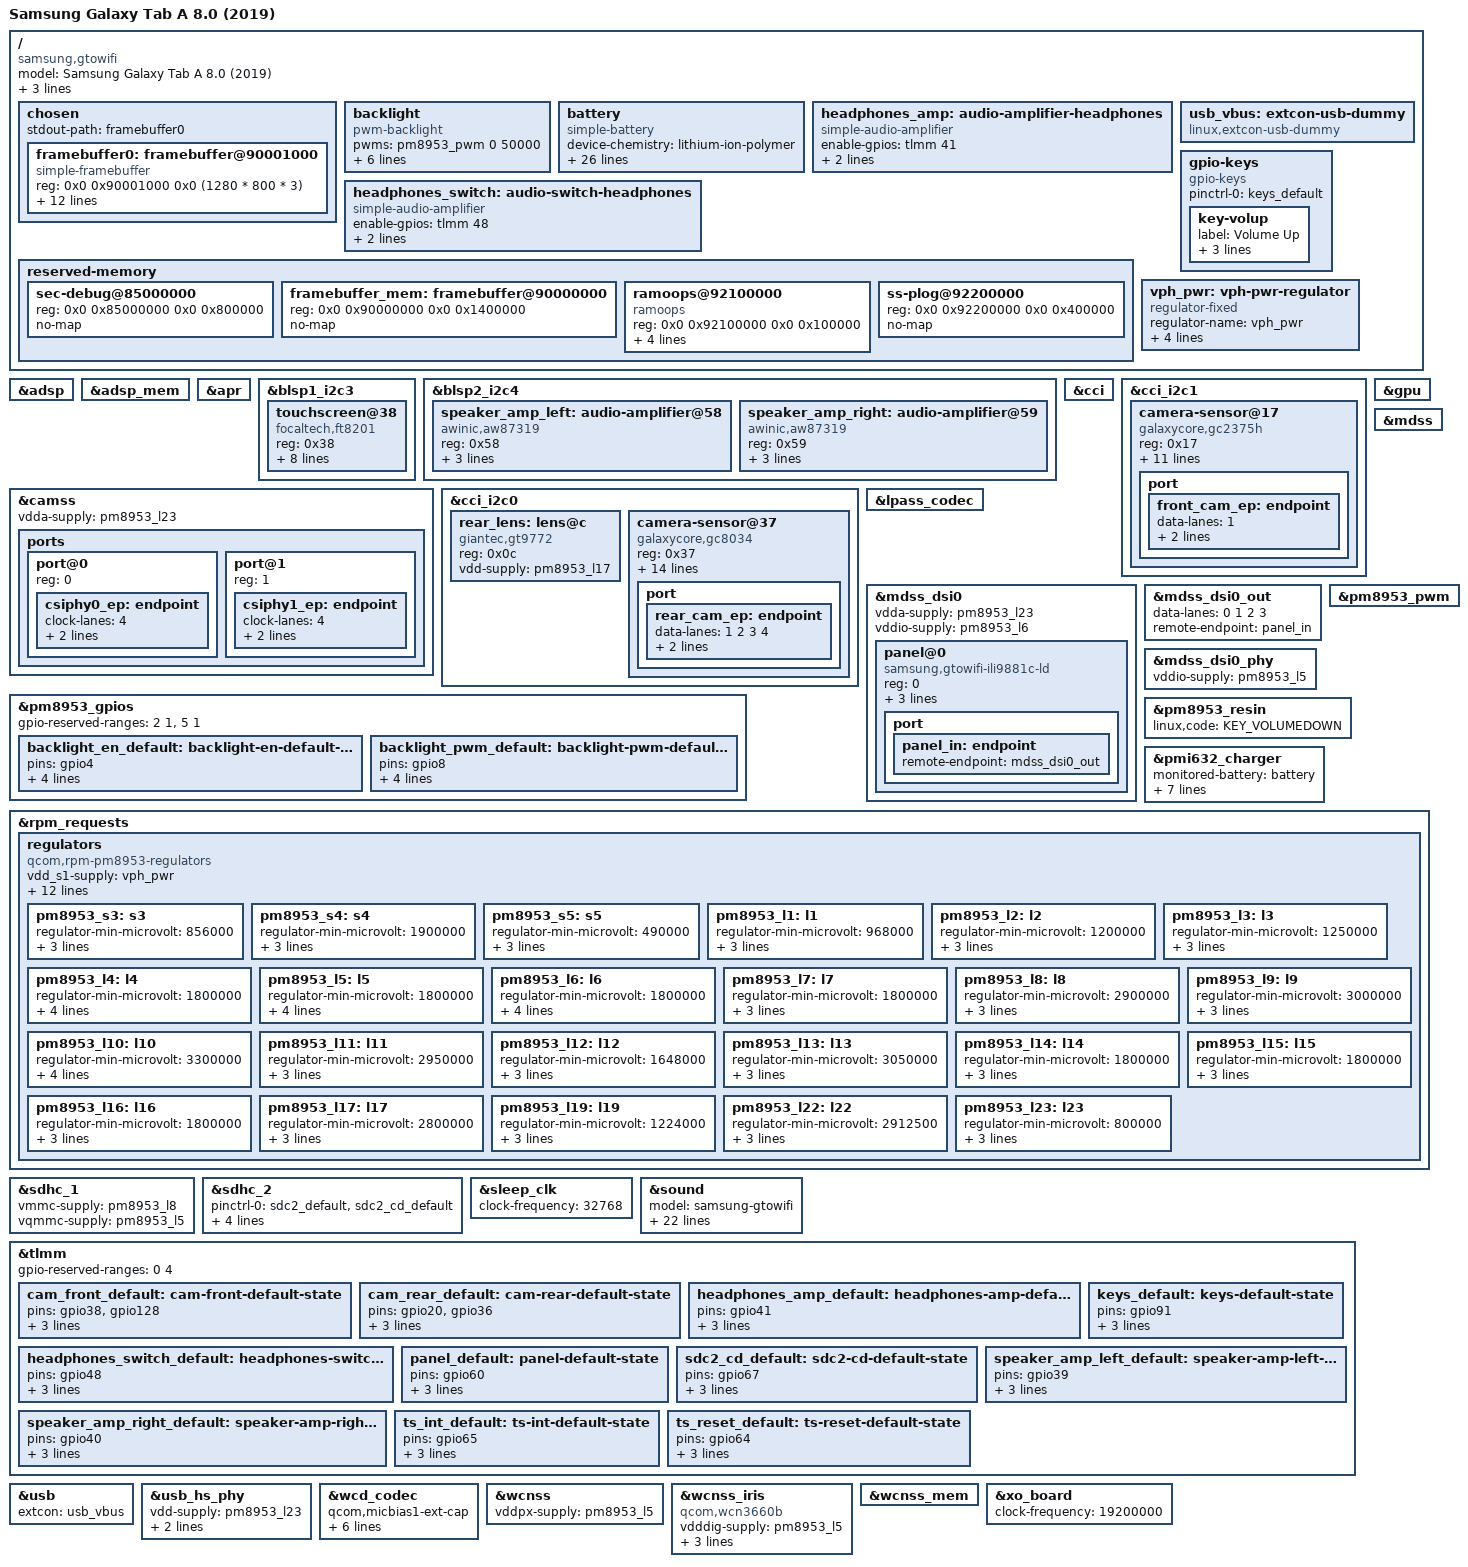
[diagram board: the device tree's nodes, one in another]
// SPDX-License-Identifier: BSD-3-Clause
/*
 * Samsung Galaxy Tab A 8.0 (2019) Wi-Fi (SM-T290, gtowifi) device tree source
 *
 * Hardware description derived from the vendor tree
 * (sdm429-mtp-P81081 overlay on top of sdm429.dts, msm-4.9).
 */

/dts-v1/;
#include <dt-bindings/arm/qcom,ids.h>
#include <dt-bindings/gpio/gpio.h>
#include <dt-bindings/pinctrl/qcom,pmic-gpio.h>
#include "sdm429.dtsi"
#include "pm8953.dtsi"
#include "pmi632.dtsi"
#include "msm8937-qdsp6.dtsi"

/ {
	model = "Samsung Galaxy Tab A 8.0 (2019)";
	compatible = "samsung,gtowifi", "qcom,sdm429";
	chassis-type = "tablet";

	qcom,msm-id = <QCOM_ID_SDM429 0>;
	qcom,board-id = <QCOM_BOARD_ID_MTP 0>;

	chosen {
		#address-cells = <2>;
		#size-cells = <2>;
		ranges;

		stdout-path = "framebuffer0";

		framebuffer0: framebuffer@90001000 {
			compatible = "simple-framebuffer";
			reg = <0x0 0x90001000 0x0 (1280 * 800 * 3)>;
			width = <800>;
			height = <1280>;
			stride = <(800 * 3)>;
			format = "r8g8b8";

			clocks = <&gcc GCC_MDSS_AHB_CLK>,
				 <&gcc GCC_MDSS_AXI_CLK>,
				 <&gcc GCC_MDSS_VSYNC_CLK>,
				 <&gcc GCC_MDSS_MDP_CLK>,
				 <&gcc GCC_MDSS_BYTE0_CLK>,
				 <&gcc GCC_MDSS_PCLK0_CLK>,
				 <&gcc GCC_MDSS_ESC0_CLK>;
			power-domains = <&gcc MDSS_GDSC>;
		};
	};

	/*
	 * Vendor: bl_ctrl_pwm on the PM8953 PWM, 50 us period (20 kHz), out on
	 * PM8953 GPIO8, enable on PM8953 GPIO4. The boot loader leaves the PWM
	 * at 286 of 511.
	 */
	backlight: backlight {
		compatible = "pwm-backlight";
		pwms = <&pm8953_pwm 0 50000>;
		enable-gpios = <&pm8953_gpios 4 GPIO_ACTIVE_HIGH>;

		brightness-levels = <0 255>;
		num-interpolated-steps = <255>;
		default-brightness-level = <143>;

		pinctrl-0 = <&backlight_pwm_default>, <&backlight_en_default>;
		pinctrl-names = "default";
	};

	/*
	 * Wingtech p81081 pack, 4980 mAh, 4.4 V. The vendor device tree carries
	 * three profiles (Scud 30 kOhm, Sunwoda 68 kOhm, Jiade 100 kOhm ID
	 * resistor) whose charge limits and 25 degC OCV tables are identical, so
	 * one node describes all of them and no id-resistor-ohms check is made
	 * (this unit: 31 kOhm, the Scud pack).
	 *
	 * The JEITA thresholds (on the charger node) are raw BAT_THERM codes. The vendor
	 * profile only gives the hard pair (0x58ce 0x1815 = 0 and 55 degC); a
	 * 100 kOhm / beta 4250 thermistor on the 100 kOhm pull-up with a full
	 * scale of 28880 reproduces both within 0.1 percent, the other codes
	 * come from that model. The vendor kernel charges at 0.5 A below
	 * 10 degC and, in software, at 0.8 A to only 4.1 V between 45 and
	 * 55 degC. The charger driver cannot lower the float voltage in the
	 * warm zone, so charging stops at 45 degC instead and the 0.8 A zone
	 * starts at 40 degC.
	 */
	battery: battery {
		compatible = "simple-battery";
		device-chemistry = "lithium-ion-polymer";
		voltage-min-design-microvolt = <3400000>;
		voltage-max-design-microvolt = <4400000>;
		charge-full-design-microamp-hours = <4980000>;
		constant-charge-current-max-microamp = <1500000>;
		constant-charge-voltage-max-microvolt = <4400000>;
		/* vendor qcom,chg-term-current-ma = -150 */
		charge-term-current-microamp = <150000>;

		/* qcom,pc-temp-v1-lut of the vendor QG profile, 25 degC column */
		ocv-capacity-celsius = <25>;
		ocv-capacity-table-0 =
			<4380500 100>, <4358400 98>, <4334400 96>, <4309700 94>,
			<4285300 92>, <4261400 90>, <4237900 88>, <4214700 86>,
			<4191900 84>, <4169300 82>, <4146900 80>, <4125300 78>,
			<4105300 76>, <4086100 74>, <4065400 72>, <4043300 70>,
			<4022800 68>, <4005100 66>, <3988800 64>, <3973600 62>,
			<3959800 60>, <3942500 58>, <3915800 56>, <3890300 54>,
			<3875900 52>, <3865500 50>, <3857000 48>, <3849900 46>,
			<3843300 44>, <3836300 42>, <3829700 40>, <3823700 38>,
			<3818400 36>, <3813500 34>, <3809300 32>, <3805400 30>,
			<3801300 28>, <3797400 26>, <3792100 24>, <3783200 22>,
			<3772100 20>, <3760600 18>, <3747700 16>, <3731800 14>,
			<3717200 12>, <3708100 10>, <3706000 9>, <3704000 8>,
			<3702300 7>, <3697700 6>, <3673000 5>, <3629900 4>,
			<3572900 3>, <3495000 2>, <3374300 1>, <3000000 0>;
	};

	/*
	 * The codec HPH outputs feed both the two speaker amplifiers and the
	 * headphone jack. The vendor kernel opens the way to the jack with a
	 * "headset amp" mixer control that drives two GPIOs high together
	 * (qcom,hph-en-gpio = TLMM 41, qcom,hph-in-gpio = TLMM 48) and low
	 * again when the headphones path is closed. The part behind them is
	 * not known, so they are described as two enables in series.
	 */
	headphones_amp: audio-amplifier-headphones {
		compatible = "simple-audio-amplifier";
		enable-gpios = <&tlmm 41 GPIO_ACTIVE_HIGH>;
		sound-name-prefix = "Headphones Amp";

		pinctrl-0 = <&headphones_amp_default>;
		pinctrl-names = "default";
	};

	headphones_switch: audio-switch-headphones {
		compatible = "simple-audio-amplifier";
		enable-gpios = <&tlmm 48 GPIO_ACTIVE_HIGH>;
		sound-name-prefix = "Headphones Switch";

		pinctrl-0 = <&headphones_switch_default>;
		pinctrl-names = "default";
	};

	usb_vbus: extcon-usb-dummy {
		compatible = "linux,extcon-usb-dummy";
	};

	gpio-keys {
		compatible = "gpio-keys";

		pinctrl-0 = <&keys_default>;
		pinctrl-names = "default";

		key-volup {
			label = "Volume Up";
			gpios = <&tlmm 91 GPIO_ACTIVE_LOW>;
			debounce-interval = <15>;
			linux,code = <KEY_VOLUMEUP>;
		};
	};

	reserved-memory {
		/* Wi-Fi only: no modem, the vendor kernel keeps ramoops here */
		/delete-node/ rmtfs@92100000;

		/* Samsung sec_debug, written by the bootloader */
		sec-debug@85000000 {
			reg = <0x0 0x85000000 0x0 0x800000>;
			no-map;
		};

		/* Vendor cont_splash region */
		framebuffer_mem: framebuffer@90000000 {
			reg = <0x0 0x90000000 0x0 0x1400000>;
			no-map;
		};

		/* Same layout as the vendor kernel, so logs survive into it */
		ramoops@92100000 {
			compatible = "ramoops";
			reg = <0x0 0x92100000 0x0 0x100000>;
			record-size = <0x40000>;
			console-size = <0x40000>;
			ftrace-size = <0x40000>;
			pmsg-size = <0x40000>;
		};

		/* Samsung ss_plog */
		ss-plog@92200000 {
			reg = <0x0 0x92200000 0x0 0x400000>;
			no-map;
		};
	};

	vph_pwr: vph-pwr-regulator {
		compatible = "regulator-fixed";
		regulator-name = "vph_pwr";
		regulator-min-microvolt = <3700000>;
		regulator-max-microvolt = <3700000>;
		regulator-always-on;
		regulator-boot-on;
	};
};

&adsp {
	status = "okay";
};

/* 0x1100000 by default, the size of the vendor adsp_fw_mem region */
&adsp_mem {
	status = "okay";
};

&apr {
	status = "okay";
};

&blsp1_i2c3 {
	status = "okay";

	touchscreen@38 {
		compatible = "focaltech,ft8201";
		reg = <0x38>;
		interrupts-extended = <&tlmm 65 IRQ_TYPE_EDGE_FALLING>;

		pinctrl-0 = <&ts_int_default &ts_reset_default>;
		pinctrl-names = "default";

		vcc-supply = <&pm8953_l10>;
		iovcc-supply = <&pm8953_l5>;
		reset-gpios = <&tlmm 64 GPIO_ACTIVE_LOW>;

		touchscreen-size-x = <800>;
		touchscreen-size-y = <1280>;
	};
};

/* Vendor i2c_8, which it runs at 400 kHz */
&blsp2_i2c4 {
	status = "okay";

	/*
	 * The reset lines have to be high for the amplifiers to work and to
	 * answer on I2C. The vendor driver drives them as raw values and
	 * ignores the flag in its device tree.
	 */
	speaker_amp_left: audio-amplifier@58 {
		compatible = "awinic,aw87319";
		reg = <0x58>;
		reset-gpios = <&tlmm 39 GPIO_ACTIVE_LOW>;
		sound-name-prefix = "Speaker Amp Left";

		pinctrl-0 = <&speaker_amp_left_default>;
		pinctrl-names = "default";
	};

	speaker_amp_right: audio-amplifier@59 {
		compatible = "awinic,aw87319";
		reg = <0x59>;
		reset-gpios = <&tlmm 40 GPIO_ACTIVE_LOW>;
		sound-name-prefix = "Speaker Amp Right";

		pinctrl-0 = <&speaker_amp_right_default>;
		pinctrl-names = "default";
	};
};

&camss {
	vdda-supply = <&pm8953_l23>;

	status = "okay";

	ports {
		port@0 {
			reg = <0>;

			csiphy0_ep: endpoint {
				clock-lanes = <4>;
				data-lanes = <0 1 2 3>;
				remote-endpoint = <&rear_cam_ep>;
			};
		};

		port@1 {
			reg = <1>;

			csiphy1_ep: endpoint {
				clock-lanes = <4>;
				data-lanes = <0>;
				remote-endpoint = <&front_cam_ep>;
			};
		};
	};
};

&cci {
	status = "okay";
};

&cci_i2c0 {
	/* Rear camera module; its GT9772 voice coil driver sits at 0x0c */
	rear_lens: lens@c {
		compatible = "giantec,gt9772";
		reg = <0x0c>;

		/* Vendor cam_vaf */
		vdd-supply = <&pm8953_l17>;
	};

	camera-sensor@37 {
		compatible = "galaxycore,gc8034";
		reg = <0x37>;

		lens-focus = <&rear_lens>;

		clocks = <&gcc GCC_CAMSS_MCLK0_CLK>;
		assigned-clocks = <&gcc GCC_CAMSS_MCLK0_CLK>;
		assigned-clock-rates = <24000000>;

		reset-gpios = <&tlmm 36 GPIO_ACTIVE_LOW>;
		powerdown-gpios = <&tlmm 20 GPIO_ACTIVE_LOW>;

		avdd-supply = <&pm8953_l22>;
		dovdd-supply = <&pm8953_l6>;
		dvdd-supply = <&pm8953_l3>;
		vaf-supply = <&pm8953_l17>;

		pinctrl-0 = <&cam_rear_default>, <&camss_mclk0_default>;
		pinctrl-names = "default";

		orientation = <1>;
		/* Vendor mount angle 90 is clockwise, this property is counter-clockwise */
		rotation = <270>;

		port {
			rear_cam_ep: endpoint {
				data-lanes = <1 2 3 4>;
				link-frequencies = /bits/ 64 <336000000 168000000>;
				remote-endpoint = <&csiphy0_ep>;
			};
		};
	};
};

&cci_i2c1 {
	camera-sensor@17 {
		compatible = "galaxycore,gc2375h";
		reg = <0x17>;

		/* The vendor software runs this sensor from 19.2 MHz */
		clocks = <&gcc GCC_CAMSS_MCLK1_CLK>;
		assigned-clocks = <&gcc GCC_CAMSS_MCLK1_CLK>;
		assigned-clock-rates = <19200000>;

		reset-gpios = <&tlmm 38 GPIO_ACTIVE_LOW>;
		powerdown-gpios = <&tlmm 128 GPIO_ACTIVE_HIGH>;

		avdd-supply = <&pm8953_l22>;
		dovdd-supply = <&pm8953_l6>;

		pinctrl-0 = <&cam_front_default>, <&camss_mclk1_default>;
		pinctrl-names = "default";

		orientation = <0>;
		/* Vendor mount angle 270, clockwise */
		rotation = <90>;

		port {
			front_cam_ep: endpoint {
				data-lanes = <1>;
				link-frequencies = /bits/ 64 <300000000>;
				remote-endpoint = <&csiphy1_ep>;
			};
		};
	};
};

&gpu {
	status = "okay";
};

&lpass_codec {
	status = "okay";
};

&mdss {
	status = "okay";
};

&mdss_dsi0 {
	/*
	 * Vendor tree (sdm439-pm8953.dtsi, confirmed in the live DT of this
	 * tablet): the DSI "vdda" rail of the 12nm parts is L23 at 0.8 V, not
	 * the 1.2 V L2 of the 28nm MSM8937. L6 is the 1.8 V supply of the
	 * vendor DSI ctrl node, which is also the only PMIC supply of the
	 * panel (its I/O voltage).
	 */
	vdda-supply = <&pm8953_l23>;
	vddio-supply = <&pm8953_l6>;

	status = "okay";

	panel@0 {
		compatible = "samsung,gtowifi-ili9881c-ld";
		reg = <0>;

		/*
		 * The panel bias (vendor "lab"/"ibb", 5.5 V from the PMI632
		 * LCDB block) has no driver here and is left as the bootloader
		 * set it up.
		 */
		backlight = <&backlight>;
		reset-gpios = <&tlmm 60 GPIO_ACTIVE_LOW>;

		pinctrl-0 = <&panel_default>;
		pinctrl-names = "default";

		port {
			panel_in: endpoint {
				remote-endpoint = <&mdss_dsi0_out>;
			};
		};
	};
};

&mdss_dsi0_out {
	data-lanes = <0 1 2 3>;
	remote-endpoint = <&panel_in>;
};

&mdss_dsi0_phy {
	/* 1.8 V "vddio" of the vendor qcom,phy-supply-entries */
	vddio-supply = <&pm8953_l5>;

	status = "okay";
};

&pm8953_gpios {
	/* GPIO3 and GPIO6 are disallowed by the vendor tree */
	gpio-reserved-ranges = <2 1>, <5 1>;

	backlight_en_default: backlight-en-default-state {
		pins = "gpio4";
		function = PMIC_GPIO_FUNC_NORMAL;
		power-source = <0>;
		bias-disable;
		output-high;
	};

	/* No vendor pinctrl entry: read from the registers the boot loader left */
	backlight_pwm_default: backlight-pwm-default-state {
		pins = "gpio8";
		function = PMIC_GPIO_FUNC_DTEST2;
		power-source = <0>;
		bias-disable;
		output-low;
	};
};

&pm8953_pwm {
	status = "okay";
};

&pm8953_resin {
	linux,code = <KEY_VOLUMEDOWN>;

	status = "okay";
};

&pmi632_charger {
	monitored-battery = <&battery>;

	qcom,connector-internal-pull-kohm = <100>;
	qcom,auto-recharge-microvolt = <4300000>;
	qcom,jeita-hard-thresholds = <0x58ce 0x20b3>;
	qcom,jeita-soft-thresholds = <0x4cbf 0x25dd>;
	qcom,jeita-soft-fcc-microamp = <500000 800000>;

	/* The vendor table starts above its own 1.5 A limit, begin there */
	qcom,thermal-mitigation = <1500000 1000000 500000>;

	status = "okay";
};

&rpm_requests {
	regulators {
		compatible = "qcom,rpm-pm8953-regulators";

		vdd_s1-supply = <&vph_pwr>;
		vdd_s2-supply = <&vph_pwr>;
		vdd_s3-supply = <&vph_pwr>;
		vdd_s4-supply = <&vph_pwr>;
		vdd_s5-supply = <&vph_pwr>;
		vdd_s6-supply = <&vph_pwr>;
		vdd_s7-supply = <&vph_pwr>;
		vdd_l1-supply = <&pm8953_s3>;
		vdd_l2_l3-supply = <&pm8953_s3>;
		vdd_l4_l5_l6_l7_l16_l19-supply = <&pm8953_s4>;
		vdd_l8_l11_l12_l13_l14_l15-supply = <&vph_pwr>;
		vdd_l9_l10_l17_l18_l22-supply = <&vph_pwr>;
		vdd_l23-supply = <&pm8953_s3>;

		pm8953_s3: s3 {
			regulator-min-microvolt = <856000>;
			regulator-max-microvolt = <1280000>;
			regulator-system-load = <100000>;
			regulator-allow-set-load;
		};

		pm8953_s4: s4 {
			regulator-min-microvolt = <1900000>;
			regulator-max-microvolt = <2040000>;
			regulator-system-load = <100000>;
			regulator-allow-set-load;
		};

		pm8953_s5: s5 {
			regulator-min-microvolt = <490000>;
			regulator-max-microvolt = <980000>;
			regulator-always-on;
			regulator-boot-on;
		};

		pm8953_l1: l1 {
			regulator-min-microvolt = <968000>;
			regulator-max-microvolt = <1152000>;
			regulator-system-load = <10000>;
			regulator-allow-set-load;
		};

		pm8953_l2: l2 {
			regulator-min-microvolt = <1200000>;
			regulator-max-microvolt = <1200000>;
			regulator-system-load = <10000>;
			regulator-allow-set-load;
		};

		pm8953_l3: l3 {
			regulator-min-microvolt = <1250000>;
			regulator-max-microvolt = <1250000>;
			regulator-system-load = <10000>;
			regulator-allow-set-load;
		};

		pm8953_l4: l4 {
			regulator-min-microvolt = <1800000>;
			regulator-max-microvolt = <1800000>;
			regulator-system-load = <10000>;
			regulator-allow-set-load;
			regulator-always-on;
		};

		pm8953_l5: l5 {
			regulator-min-microvolt = <1800000>;
			regulator-max-microvolt = <1800000>;
			regulator-system-load = <10000>;
			regulator-allow-set-load;
			regulator-always-on;
		};

		pm8953_l6: l6 {
			regulator-min-microvolt = <1800000>;
			regulator-max-microvolt = <1800000>;
			regulator-system-load = <10000>;
			regulator-allow-set-load;
			regulator-always-on;
		};

		pm8953_l7: l7 {
			regulator-min-microvolt = <1800000>;
			regulator-max-microvolt = <1800000>;
			regulator-system-load = <10000>;
			regulator-allow-set-load;
		};

		pm8953_l8: l8 {
			regulator-min-microvolt = <2900000>;
			regulator-max-microvolt = <2900000>;
			regulator-system-load = <10000>;
			regulator-allow-set-load;
		};

		pm8953_l9: l9 {
			regulator-min-microvolt = <3000000>;
			regulator-max-microvolt = <3300000>;
			regulator-system-load = <10000>;
			regulator-allow-set-load;
		};

		/* Touchscreen VDD, kept on by the vendor kernel */
		pm8953_l10: l10 {
			regulator-min-microvolt = <3300000>;
			regulator-max-microvolt = <3300000>;
			regulator-system-load = <10000>;
			regulator-allow-set-load;
			regulator-always-on;
		};

		/*
		 * SD card supply: the vendor kernel runs it at a fixed 2.95 V.
		 * A wider range makes the MMC core ask L12 (I/O, capped at
		 * 3.1 V by the vendor) for 3.3 V.
		 */
		pm8953_l11: l11 {
			regulator-min-microvolt = <2950000>;
			regulator-max-microvolt = <2950000>;
			regulator-system-load = <10000>;
			regulator-allow-set-load;
		};

		pm8953_l12: l12 {
			regulator-min-microvolt = <1648000>;
			regulator-max-microvolt = <3100000>;
			regulator-system-load = <10000>;
			regulator-allow-set-load;
		};

		pm8953_l13: l13 {
			regulator-min-microvolt = <3050000>;
			regulator-max-microvolt = <3100000>;
			regulator-system-load = <5000>;
			regulator-allow-set-load;
		};

		pm8953_l14: l14 {
			regulator-min-microvolt = <1800000>;
			regulator-max-microvolt = <3052000>;
			regulator-system-load = <5000>;
			regulator-allow-set-load;
		};

		pm8953_l15: l15 {
			regulator-min-microvolt = <1800000>;
			regulator-max-microvolt = <3052000>;
			regulator-system-load = <5000>;
			regulator-allow-set-load;
		};

		pm8953_l16: l16 {
			regulator-min-microvolt = <1800000>;
			regulator-max-microvolt = <1800000>;
			regulator-system-load = <5000>;
			regulator-allow-set-load;
		};

		pm8953_l17: l17 {
			regulator-min-microvolt = <2800000>;
			regulator-max-microvolt = <2900000>;
			regulator-system-load = <10000>;
			regulator-allow-set-load;
		};

		pm8953_l19: l19 {
			regulator-min-microvolt = <1224000>;
			regulator-max-microvolt = <1356000>;
			regulator-system-load = <10000>;
			regulator-allow-set-load;
		};

		/* Vendor asks for 2.92 V, which is between two 12.5 mV steps */
		pm8953_l22: l22 {
			regulator-min-microvolt = <2912500>;
			regulator-max-microvolt = <2925000>;
			regulator-system-load = <10000>;
			regulator-allow-set-load;
		};

		pm8953_l23: l23 {
			regulator-min-microvolt = <800000>;
			regulator-max-microvolt = <1000000>;
			regulator-system-load = <10000>;
			regulator-allow-set-load;
		};
	};
};

&sdhc_1 {
	vmmc-supply = <&pm8953_l8>;
	vqmmc-supply = <&pm8953_l5>;

	status = "okay";
};

&sdhc_2 {
	pinctrl-0 = <&sdc2_default &sdc2_cd_default>;
	pinctrl-1 = <&sdc2_sleep &sdc2_cd_default>;
	pinctrl-names = "default", "sleep";

	vmmc-supply = <&pm8953_l11>;
	vqmmc-supply = <&pm8953_l12>;
	cd-gpios = <&tlmm 67 GPIO_ACTIVE_HIGH>;

	status = "okay";
};

&sleep_clk {
	clock-frequency = <32768>;
};

&sound {
	model = "samsung-gtowifi";

	aux-devs = <&speaker_amp_left>, <&speaker_amp_right>,
		   <&headphones_amp>, <&headphones_switch>;
	widgets = "Speaker", "Speaker",
		  "Headphone", "Headphones";
	pin-switches = "Speaker", "Headphones";
	audio-routing = "Speaker", "Speaker Amp Left OUT",
			"Speaker", "Speaker Amp Right OUT",
			"Speaker Amp Left IN", "HPH_L",
			"Speaker Amp Right IN", "HPH_R",
			"Headphones", "Headphones Switch OUTL",
			"Headphones", "Headphones Switch OUTR",
			"Headphones Switch INL", "Headphones Amp OUTL",
			"Headphones Switch INR", "Headphones Amp OUTR",
			"Headphones Amp INL", "HPH_L",
			"Headphones Amp INR", "HPH_R",
			"AMIC1", "MIC BIAS External1",
			"AMIC2", "MIC BIAS Internal2",
			"AMIC3", "MIC BIAS External1",
			"MM_DL1", "MultiMedia1 Playback",
			"MM_DL3", "MultiMedia3 Playback",
			"MM_DL4", "MultiMedia4 Playback",
			"MultiMedia2 Capture", "MM_UL2";

	status = "okay";

	/* Wi-Fi only: no modem, no voice calls */
	/delete-node/ voicemmode1-dai-link;
};

&tlmm {
	/* Owned by TZ: the vendor kernel refuses to touch these */
	gpio-reserved-ranges = <0 4>;

	cam_front_default: cam-front-default-state {
		pins = "gpio38", "gpio128";
		function = "gpio";
		drive-strength = <2>;
		bias-disable;
	};

	cam_rear_default: cam-rear-default-state {
		pins = "gpio20", "gpio36";
		function = "gpio";
		drive-strength = <2>;
		bias-disable;
	};

	/*
	 * The vendor kernel leaves the four audio enable lines at their
	 * pull-down, which keeps the amplifiers off while nothing drives them.
	 */
	headphones_amp_default: headphones-amp-default-state {
		pins = "gpio41";
		function = "gpio";
		drive-strength = <2>;
		bias-pull-down;
	};

	headphones_switch_default: headphones-switch-default-state {
		pins = "gpio48";
		function = "gpio";
		drive-strength = <2>;
		bias-pull-down;
	};

	keys_default: keys-default-state {
		pins = "gpio91";
		function = "gpio";
		drive-strength = <2>;
		bias-pull-up;
	};

	panel_default: panel-default-state {
		pins = "gpio60";
		function = "gpio";
		drive-strength = <8>;
		bias-disable;
	};

	sdc2_cd_default: sdc2-cd-default-state {
		pins = "gpio67";
		function = "gpio";
		drive-strength = <2>;
		bias-disable;
	};

	speaker_amp_left_default: speaker-amp-left-default-state {
		pins = "gpio39";
		function = "gpio";
		drive-strength = <2>;
		bias-pull-down;
	};

	speaker_amp_right_default: speaker-amp-right-default-state {
		pins = "gpio40";
		function = "gpio";
		drive-strength = <2>;
		bias-pull-down;
	};

	ts_int_default: ts-int-default-state {
		pins = "gpio65";
		function = "gpio";
		drive-strength = <8>;
		bias-pull-up;
	};

	ts_reset_default: ts-reset-default-state {
		pins = "gpio64";
		function = "gpio";
		drive-strength = <8>;
		bias-pull-up;
	};
};

&usb {
	extcon = <&usb_vbus>;

	status = "okay";
};

&usb_hs_phy {
	vdd-supply = <&pm8953_l23>;
	vdda1p8-supply = <&pm8953_l7>;
	vdda3p3-supply = <&pm8953_l13>;

	status = "okay";
};

/*
 * Vendor: qcom,msm-micbias1-ext-cap, qcom,msm-mbhc-hphl-swh = <1> (normally
 * open), qcom,msm-mbhc-gnd-swh = <0> (normally closed) and the Wingtech
 * button thresholds of def_msm8952_wcd_mbhc_cal(), the same for the
 * current source and for micbias. The US/EURO switch (TLMM 63, which the
 * vendor kernel drives low) has no mainline support and is left alone.
 */
&wcd_codec {
	qcom,micbias1-ext-cap;
	qcom,hphl-jack-type-normally-open;
	qcom,mbhc-vthreshold-low = <75 225 450 500 500>;
	qcom,mbhc-vthreshold-high = <75 225 450 500 500>;

	vdd-cdc-io-supply = <&pm8953_l5>;
	vdd-cdc-tx-rx-cx-supply = <&pm8953_s4>;
	vdd-micbias-supply = <&pm8953_l13>;

	status = "okay";
};

&wcnss {
	vddpx-supply = <&pm8953_l5>;

	status = "okay";
};

&wcnss_iris {
	compatible = "qcom,wcn3660b";

	vdddig-supply = <&pm8953_l5>;
	vddpa-supply = <&pm8953_l9>;
	vddrfa-supply = <&pm8953_l19>;
	vddxo-supply = <&pm8953_l7>;
};

&wcnss_mem {
	status = "okay";
};

&xo_board {
	clock-frequency = <19200000>;
};
